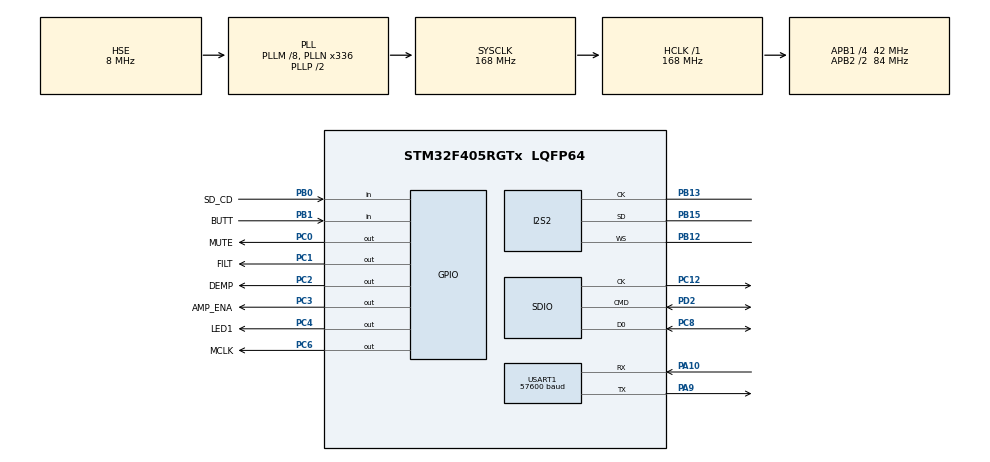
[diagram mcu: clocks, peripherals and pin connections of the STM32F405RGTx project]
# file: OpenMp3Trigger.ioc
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Dma.Request0=SDIO_RX
Dma.Request1=SDIO_TX
Dma.Request2=SPI2_TX
Dma.SDIO_RX.0.Direction=DMA_PERIPH_TO_MEMORY
Dma.SDIO_RX.0.FIFOMode=DMA_FIFOMODE_ENABLE
Dma.SDIO_RX.0.FIFOThreshold=DMA_FIFO_THRESHOLD_FULL
Dma.SDIO_RX.0.Instance=DMA2_Stream3
Dma.SDIO_RX.0.MemBurst=DMA_MBURST_INC4
Dma.SDIO_RX.0.MemDataAlignment=DMA_MDATAALIGN_WORD
Dma.SDIO_RX.0.MemInc=DMA_MINC_ENABLE
Dma.SDIO_RX.0.Mode=DMA_PFCTRL
Dma.SDIO_RX.0.PeriphBurst=DMA_PBURST_INC4
Dma.SDIO_RX.0.PeriphDataAlignment=DMA_PDATAALIGN_WORD
Dma.SDIO_RX.0.PeriphInc=DMA_PINC_DISABLE
Dma.SDIO_RX.0.Priority=DMA_PRIORITY_LOW
Dma.SDIO_TX.1.Direction=DMA_MEMORY_TO_PERIPH
Dma.SDIO_TX.1.FIFOMode=DMA_FIFOMODE_ENABLE
Dma.SDIO_TX.1.FIFOThreshold=DMA_FIFO_THRESHOLD_FULL
Dma.SDIO_TX.1.Instance=DMA2_Stream6
Dma.SDIO_TX.1.MemBurst=DMA_MBURST_INC4
Dma.SDIO_TX.1.MemDataAlignment=DMA_MDATAALIGN_WORD
Dma.SDIO_TX.1.MemInc=DMA_MINC_ENABLE
Dma.SDIO_TX.1.Mode=DMA_PFCTRL
Dma.SDIO_TX.1.PeriphBurst=DMA_PBURST_INC4
Dma.SDIO_TX.1.PeriphDataAlignment=DMA_PDATAALIGN_WORD
Dma.SDIO_TX.1.PeriphInc=DMA_PINC_DISABLE
Dma.SDIO_TX.1.Priority=DMA_PRIORITY_LOW
Dma.SPI2_TX.2.Direction=DMA_MEMORY_TO_PERIPH
Dma.SPI2_TX.2.FIFOMode=DMA_FIFOMODE_DISABLE
Dma.SPI2_TX.2.Instance=DMA1_Stream4
Dma.SPI2_TX.2.MemDataAlignment=DMA_MDATAALIGN_WORD
Dma.SPI2_TX.2.MemInc=DMA_MINC_ENABLE
Dma.SPI2_TX.2.Mode=DMA_CIRCULAR
Dma.SPI2_TX.2.PeriphDataAlignment=DMA_PDATAALIGN_WORD
Dma.SPI2_TX.2.PeriphInc=DMA_PINC_DISABLE
Dma.SPI2_TX.2.Priority=DMA_PRIORITY_LOW
I2S2.AudioFreq=I2S_AUDIOFREQ_44K
I2S2.DataFormat=I2S_DATAFORMAT_32B
I2S2.ErrorAudioFreq=0.24 %
I2S2.FullDuplexMode=I2S_FULLDUPLEXMODE_DISABLE
I2S2.Instance=SPI$Index
I2S2.RealAudioFreq=44.108 KHz
I2S2.VirtualMode=I2S_MODE_MASTER
Mcu.Family=STM32F4
Mcu.Name=STM32F405RGTx
Mcu.Package=LQFP64
NVIC.DMA1_Stream4_IRQn=true\:0\:0\:false\:false\:true\:false\:true\:true
NVIC.DMA2_Stream3_IRQn=true\:0\:0\:false\:false\:true\:false\:true\:true
NVIC.DMA2_Stream6_IRQn=true\:0\:0\:false\:false\:true\:false\:true\:true
NVIC.PriorityGroup=NVIC_PRIORITYGROUP_4
NVIC.SDIO_IRQn=true\:0\:0\:false\:false\:true\:true\:true\:true
NVIC.SPI2_IRQn=true\:0\:0\:false\:false\:true\:true\:true\:true
NVIC.USART1_IRQn=true\:0\:0\:false\:false\:true\:true\:true\:true
PA10.Mode=Asynchronous
PA10.Signal=USART1_RX
PA9.Mode=Asynchronous
PA9.Signal=USART1_TX
PB0.GPIO_Label=SD_CD
PB0.GPIO_Mode=GPIO_MODE_INPUT
PB0.GPIO_PuPd=GPIO_PULLUP
PB0.Signal=GPIO_Input
PB1.GPIO_Label=BUTT
PB1.GPIO_PuPd=GPIO_PULLUP
PB1.Signal=GPIO_Input
PB12.Mode=Half_Duplex_Master
PB12.Signal=I2S2_WS
PB13.Mode=Half_Duplex_Master
PB13.Signal=I2S2_CK
PB15.Mode=Half_Duplex_Master
PB15.Signal=I2S2_SD
PC0.GPIO_Label=MUTE
PC0.Signal=GPIO_Output
PC1.GPIO_Label=FILT
PC1.Signal=GPIO_Output
PC10.Signal=SDIO_D2
PC11.Signal=SDIO_D3
PC12.Mode=SD_1_bit
PC12.Signal=SDIO_CK
PC2.GPIO_Label=DEMP
PC2.Signal=GPIO_Output
PC3.GPIO_Label=AMP_ENA
PC3.Signal=GPIO_Output
PC4.GPIO_Label=LED1
PC4.Signal=GPIO_Output
PC6.GPIO_Label=MCLK
PC6.Signal=GPIO_Output
PC8.Mode=SD_1_bit
PC8.Signal=SDIO_D0
PC9.Signal=SDIO_D1
PD2.Mode=SD_1_bit
PD2.Signal=SDIO_CMD
PH0-OSC_IN.Mode=HSE-External-Oscillator
PH0-OSC_IN.Signal=RCC_OSC_IN
PH1-OSC_OUT.Mode=HSE-External-Oscillator
PH1-OSC_OUT.Signal=RCC_OSC_OUT
ProjectManager.HeapSize=0x200
ProjectManager.StackSize=0x800
ProjectManager.TargetToolchain=CMake
RCC.48MHZClocksFreq_Value=48000000
RCC.AHBFreq_Value=168000000
RCC.APB1CLKDivider=RCC_HCLK_DIV4
RCC.APB1Freq_Value=42000000
RCC.APB1TimFreq_Value=84000000
RCC.APB2CLKDivider=RCC_HCLK_DIV2
RCC.APB2Freq_Value=84000000
RCC.APB2TimFreq_Value=168000000
RCC.CortexFreq_Value=168000000
RCC.HCLKFreq_Value=168000000
RCC.HSE_VALUE=8000000
RCC.HSI_VALUE=16000000
RCC.LSE_VALUE=32768
RCC.PLLI2SN=271
RCC.PLLM=8
RCC.PLLN=336
RCC.PLLQ=7
RCC.PLLSourceVirtual=RCC_PLLSOURCE_HSE
RCC.SYSCLKFreq_VALUE=168000000
RCC.SYSCLKSource=RCC_SYSCLKSOURCE_PLLCLK
RCC.VCOOutputFreq_Value=336000000
SDIO.ClockDiv=0
TIM2.Prescaler=84
USART1.BaudRate=57600
USART1.VirtualMode=VM_ASYNC
VP_TIM2_VS_ClockSourceINT.Mode=Internal
board=custom

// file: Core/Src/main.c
/* USER CODE BEGIN Header */
/**
  ******************************************************************************
  * @file           : main.c
  * @brief          : Main program body
  ******************************************************************************
  * @attention
  *
  * Copyright (c) 2025 STMicroelectronics.
  * All rights reserved.
  *
  * This software is licensed under terms that can be found in the LICENSE file
  * in the root directory of this software component.
  * If no LICENSE file comes with this software, it is provided AS-IS.
  *
  ******************************************************************************
  */
/* USER CODE END Header */
#include "main.h"

/* USER CODE BEGIN Includes */

#include "player.h"

/* USER CODE END Includes */

I2S_HandleTypeDef hi2s2;
DMA_HandleTypeDef hdma_spi2_tx;

SD_HandleTypeDef hsd;
DMA_HandleTypeDef hdma_sdio_rx;
DMA_HandleTypeDef hdma_sdio_tx;

/* USER CODE BEGIN PV */

extern volatile uint8_t gSysFlags;				// System init error flags

/* USER CODE END PV */

void SystemClock_Config(void);
static void MX_GPIO_Init(void);
static void MX_DMA_Init(void);
static void MX_SDIO_SD_Init(void);
static void MX_USART1_UART_Init(void);
static void MX_TIM2_Init(void);
static void MX_I2S2_Init(void);

int main(void)
{

  /* MCU Configuration--------------------------------------------------------*/

  /* Reset of all peripherals, Initializes the Flash interface and the Systick. */
  HAL_Init();

  /* Configure the system clock */
  SystemClock_Config();

  /* Initialize all configured peripherals */
  MX_GPIO_Init();
  MX_DMA_Init();
  MX_SDIO_SD_Init();
  MX_USART1_UART_Init();
  MX_TIM2_Init();
  MX_I2S2_Init();
  /* USER CODE BEGIN 2 */

  sdTestInit();

  /* USER CODE END 2 */

  /* Infinite loop */
  /* USER CODE BEGIN WHILE */
  while (1)
  {

    sdTestProcess();

    /* USER CODE END WHILE */

  }
}

void SystemClock_Config(void)
{
  RCC_OscInitTypeDef RCC_OscInitStruct = {0};
  RCC_ClkInitTypeDef RCC_ClkInitStruct = {0};

  /** Configure the main internal regulator output voltage
  */
  __HAL_RCC_PWR_CLK_ENABLE();
  __HAL_PWR_VOLTAGESCALING_CONFIG(PWR_REGULATOR_VOLTAGE_SCALE1);

  /** Initializes the RCC Oscillators according to the specified parameters
  * in the RCC_OscInitTypeDef structure.
  */
  RCC_OscInitStruct.OscillatorType = RCC_OSCILLATORTYPE_HSE;
  RCC_OscInitStruct.HSEState = RCC_HSE_ON;
  RCC_OscInitStruct.PLL.PLLState = RCC_PLL_ON;
  RCC_OscInitStruct.PLL.PLLSource = RCC_PLLSOURCE_HSE;
  RCC_OscInitStruct.PLL.PLLM = 8;
  RCC_OscInitStruct.PLL.PLLN = 336;
  RCC_OscInitStruct.PLL.PLLP = RCC_PLLP_DIV2;
  RCC_OscInitStruct.PLL.PLLQ = 7;
  if (HAL_RCC_OscConfig(&RCC_OscInitStruct) != HAL_OK)
  {
    Error_Handler();
  }

  /** Initializes the CPU, AHB and APB buses clocks
  */
  RCC_ClkInitStruct.ClockType = RCC_CLOCKTYPE_HCLK|RCC_CLOCKTYPE_SYSCLK
                              |RCC_CLOCKTYPE_PCLK1|RCC_CLOCKTYPE_PCLK2;
  RCC_ClkInitStruct.SYSCLKSource = RCC_SYSCLKSOURCE_PLLCLK;
  RCC_ClkInitStruct.AHBCLKDivider = RCC_SYSCLK_DIV1;
  RCC_ClkInitStruct.APB1CLKDivider = RCC_HCLK_DIV4;
  RCC_ClkInitStruct.APB2CLKDivider = RCC_HCLK_DIV2;

  if (HAL_RCC_ClockConfig(&RCC_ClkInitStruct, FLASH_LATENCY_5) != HAL_OK)
  {
    Error_Handler();
  }
}

static void MX_I2S2_Init(void)
{

  hi2s2.Instance = SPI2;
  hi2s2.Init.Mode = I2S_MODE_MASTER_TX;
  hi2s2.Init.Standard = I2S_STANDARD_PHILIPS;
  hi2s2.Init.DataFormat = I2S_DATAFORMAT_32B;
  hi2s2.Init.MCLKOutput = I2S_MCLKOUTPUT_DISABLE;
  hi2s2.Init.AudioFreq = I2S_AUDIOFREQ_44K;
  hi2s2.Init.CPOL = I2S_CPOL_LOW;
  hi2s2.Init.ClockSource = I2S_CLOCK_PLL;
  hi2s2.Init.FullDuplexMode = I2S_FULLDUPLEXMODE_DISABLE;
  if (HAL_I2S_Init(&hi2s2) != HAL_OK)
  {
    Error_Handler();
  }

}

static void MX_SDIO_SD_Init(void)
{

  /* USER CODE BEGIN SDIO_Init 0 */

  // Give the microSD card a chance to power up
  HAL_Delay(100);

  // Now check to see if there's anything in the SD socket
  if (!biosIsSdCardInstalled()) {
    gSysFlags = SYS_FATAL_ERROR;
    return;
  }

  /* USER CODE END SDIO_Init 0 */

  hsd.Instance = SDIO;
  hsd.Init.ClockEdge = SDIO_CLOCK_EDGE_RISING;
  hsd.Init.ClockBypass = SDIO_CLOCK_BYPASS_DISABLE;
  hsd.Init.ClockPowerSave = SDIO_CLOCK_POWER_SAVE_DISABLE;
  hsd.Init.BusWide = SDIO_BUS_WIDE_1B;
  hsd.Init.HardwareFlowControl = SDIO_HARDWARE_FLOW_CONTROL_DISABLE;
  hsd.Init.ClockDiv = 0;
  if (HAL_SD_Init(&hsd) != HAL_OK)
  {
    Error_Handler();
  }
  /* USER CODE BEGIN SDIO_Init 2 */

  if (HAL_SD_ConfigWideBusOperation(&hsd, SDIO_BUS_WIDE_4B) != HAL_OK)
  {
      Error_Handler();
  }

  /* USER CODE END SDIO_Init 2 */

}

static void MX_TIM2_Init(void)
{

  LL_TIM_InitTypeDef TIM_InitStruct = {0};

  /* Peripheral clock enable */
  LL_APB1_GRP1_EnableClock(LL_APB1_GRP1_PERIPH_TIM2);

  TIM_InitStruct.Prescaler = 84;
  TIM_InitStruct.CounterMode = LL_TIM_COUNTERMODE_UP;
  TIM_InitStruct.Autoreload = 4294967295;
  TIM_InitStruct.ClockDivision = LL_TIM_CLOCKDIVISION_DIV1;
  LL_TIM_Init(TIM2, &TIM_InitStruct);
  LL_TIM_DisableARRPreload(TIM2);
  LL_TIM_SetClockSource(TIM2, LL_TIM_CLOCKSOURCE_INTERNAL);
  LL_TIM_SetTriggerOutput(TIM2, LL_TIM_TRGO_RESET);
  LL_TIM_DisableMasterSlaveMode(TIM2);

}

static void MX_USART1_UART_Init(void)
{

  LL_USART_InitTypeDef USART_InitStruct = {0};

  LL_GPIO_InitTypeDef GPIO_InitStruct = {0};

  /* Peripheral clock enable */
  LL_APB2_GRP1_EnableClock(LL_APB2_GRP1_PERIPH_USART1);

  LL_AHB1_GRP1_EnableClock(LL_AHB1_GRP1_PERIPH_GPIOA);
  /**USART1 GPIO Configuration
  PA9   ------> USART1_TX
  PA10   ------> USART1_RX
  */
  GPIO_InitStruct.Pin = LL_GPIO_PIN_9|LL_GPIO_PIN_10;
  GPIO_InitStruct.Mode = LL_GPIO_MODE_ALTERNATE;
  GPIO_InitStruct.Speed = LL_GPIO_SPEED_FREQ_VERY_HIGH;
  GPIO_InitStruct.OutputType = LL_GPIO_OUTPUT_PUSHPULL;
  GPIO_InitStruct.Pull = LL_GPIO_PULL_NO;
  GPIO_InitStruct.Alternate = LL_GPIO_AF_7;
  LL_GPIO_Init(GPIOA, &GPIO_InitStruct);

  /* USART1 interrupt Init */
  NVIC_SetPriority(USART1_IRQn, NVIC_EncodePriority(NVIC_GetPriorityGrouping(),0, 0));
  NVIC_EnableIRQ(USART1_IRQn);

  USART_InitStruct.BaudRate = 57600;
  USART_InitStruct.DataWidth = LL_USART_DATAWIDTH_8B;
  USART_InitStruct.StopBits = LL_USART_STOPBITS_1;
  USART_InitStruct.Parity = LL_USART_PARITY_NONE;
  USART_InitStruct.TransferDirection = LL_USART_DIRECTION_TX_RX;
  USART_InitStruct.HardwareFlowControl = LL_USART_HWCONTROL_NONE;
  USART_InitStruct.OverSampling = LL_USART_OVERSAMPLING_16;
  LL_USART_Init(USART1, &USART_InitStruct);
  LL_USART_ConfigAsyncMode(USART1);
  LL_USART_Enable(USART1);

}

static void MX_DMA_Init(void)
{

  /* DMA controller clock enable */
  __HAL_RCC_DMA2_CLK_ENABLE();
  __HAL_RCC_DMA1_CLK_ENABLE();

  /* DMA interrupt init */
  /* DMA1_Stream4_IRQn interrupt configuration */
  HAL_NVIC_SetPriority(DMA1_Stream4_IRQn, 0, 0);
  HAL_NVIC_EnableIRQ(DMA1_Stream4_IRQn);
  /* DMA2_Stream3_IRQn interrupt configuration */
  HAL_NVIC_SetPriority(DMA2_Stream3_IRQn, 0, 0);
  HAL_NVIC_EnableIRQ(DMA2_Stream3_IRQn);
  /* DMA2_Stream6_IRQn interrupt configuration */
  HAL_NVIC_SetPriority(DMA2_Stream6_IRQn, 0, 0);
  HAL_NVIC_EnableIRQ(DMA2_Stream6_IRQn);

}

static void MX_GPIO_Init(void)
{
  GPIO_InitTypeDef GPIO_InitStruct = {0};

  /* GPIO Ports Clock Enable */
  __HAL_RCC_GPIOH_CLK_ENABLE();
  __HAL_RCC_GPIOC_CLK_ENABLE();
  __HAL_RCC_GPIOB_CLK_ENABLE();
  __HAL_RCC_GPIOA_CLK_ENABLE();
  __HAL_RCC_GPIOD_CLK_ENABLE();

  /*Configure GPIO pin Output Level */
  HAL_GPIO_WritePin(GPIOC, MUTE_Pin|FILT_Pin|DEMP_Pin|AMP_ENA_Pin
                          |LED1_Pin|MCLK_Pin, GPIO_PIN_RESET);

  /*Configure GPIO pins : MUTE_Pin FILT_Pin DEMP_Pin AMP_ENA_Pin
                           LED1_Pin MCLK_Pin */
  GPIO_InitStruct.Pin = MUTE_Pin|FILT_Pin|DEMP_Pin|AMP_ENA_Pin
                          |LED1_Pin|MCLK_Pin;
  GPIO_InitStruct.Mode = GPIO_MODE_OUTPUT_PP;
  GPIO_InitStruct.Pull = GPIO_NOPULL;
  GPIO_InitStruct.Speed = GPIO_SPEED_FREQ_LOW;
  HAL_GPIO_Init(GPIOC, &GPIO_InitStruct);

  /*Configure GPIO pins : SD_CD_Pin BUTT_Pin */
  GPIO_InitStruct.Pin = SD_CD_Pin|BUTT_Pin;
  GPIO_InitStruct.Mode = GPIO_MODE_INPUT;
  GPIO_InitStruct.Pull = GPIO_PULLUP;
  HAL_GPIO_Init(GPIOB, &GPIO_InitStruct);

}

void Error_Handler(void)
{
  __disable_irq();
  while (1)
  {
  }
}
